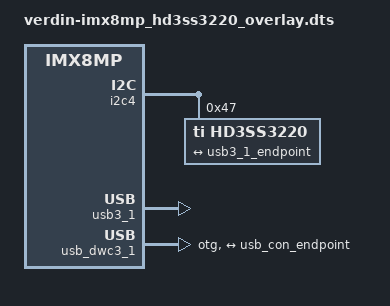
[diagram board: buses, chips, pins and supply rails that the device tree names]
/dts-v1/;
/plugin/;

#include <dt-bindings/gpio/gpio.h>
#include <dt-bindings/usb/pd.h>

/ {
    compatible = "toradex,verdin-imx8mp";

    /* Cấu hình chip HD3SS3220 trên bus I2C4 */
    fragment@0 {
        target = <&i2c4>;
        __overlay__ {
            #address-cells = <1>;
            #size-cells = <0>;
            status = "okay";

            hd3ss3220@47 {
                compatible = "ti,hd3ss3220";
                reg = <0x47>;
                status = "okay";
                
                connector {
                    compatible = "usb-c-connector";
                    label = "USB-C-SS";
                    data-role = "dual";
                    power-role = "dual";
                    try-power-role = "sink";

                    ports {
                        #address-cells = <1>;
                        #size-cells = <0>;
                        port@0 {
                            reg = <0>;
                            usb_con_endpoint: endpoint {
                                remote-endpoint = <&usb3_1_endpoint>;
                            };
                        };
                    };
                };
            };
        };
    };

    /* Cấu hình USB2 Controller (wrapper) */
    fragment@1 {
        target = <&usb3_1>;
        __overlay__ {
            status = "okay";
        };
    };

    /* Cấu hình dwc3 core bên trong để bẻ gãy dependency cycle */
    fragment@2 {
        target = <&usb_dwc3_1>;
        __overlay__ {
            dr_mode = "otg";
            usb-role-switch;
            role-switch-default-mode = "peripheral";
            
            port {
                usb3_1_endpoint: endpoint {
                    remote-endpoint = <&usb_con_endpoint>;
                };
            };
        };
    };
};
